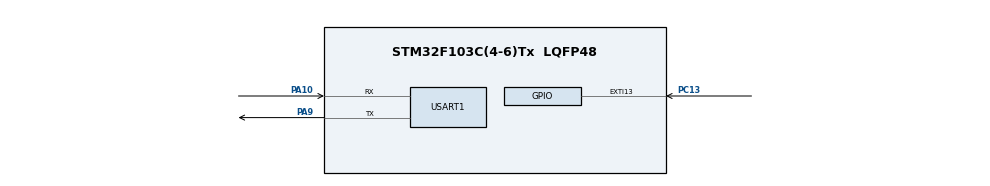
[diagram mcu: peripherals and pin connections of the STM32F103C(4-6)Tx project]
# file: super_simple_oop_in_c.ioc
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FREERTOS.Tasks01=mainTask,24,128,StartMainTask,Default,NULL,Dynamic,NULL,NULL
Mcu.Family=STM32F1
Mcu.Name=STM32F103C(4-6)Tx
Mcu.Package=LQFP48
NVIC.PriorityGroup=NVIC_PRIORITYGROUP_4
NVIC.TIM1_UP_IRQn=true\:15\:0\:false\:false\:true\:false\:false\:true\:true
NVIC.TimeBase=TIM1_UP_IRQn
NVIC.TimeBaseIP=TIM1
PA10.Mode=Asynchronous
PA10.Signal=USART1_RX
PA9.Mode=Asynchronous
PA9.Signal=USART1_TX
PC13-TAMPER-RTC.Signal=GPXTI13
ProjectManager.HeapSize=0x200
ProjectManager.StackSize=0x400
ProjectManager.TargetToolchain=Makefile
RCC.APB1Freq_Value=8000000
RCC.APB2Freq_Value=8000000
USART1.VirtualMode=VM_ASYNC
VP_FREERTOS_VS_CMSIS_V2.Mode=CMSIS_V2
VP_SYS_VS_ND.Mode=No_Debug
VP_SYS_VS_tim1.Mode=TIM1
board=custom

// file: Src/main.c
/* USER CODE BEGIN Header */
/**
 ******************************************************************************
 * @file           : main.c
 * @brief          : Main program body
 ******************************************************************************
 * @attention
 *
 * Copyright (c) 2023 STMicroelectronics.
 * All rights reserved.
 *
 * This software is licensed under terms that can be found in the LICENSE file
 * in the root directory of this software component.
 * If no LICENSE file comes with this software, it is provided AS-IS.
 *
 ******************************************************************************
 */
/* USER CODE END Header */
#include "main.h"
#include "cmsis_os.h"
#include "usart.h"
#include "gpio.h"

void SystemClock_Config(void);
void MX_FREERTOS_Init(void);

int main(void)
{

  /* MCU Configuration--------------------------------------------------------*/

  /* Reset of all peripherals, Initializes the Flash interface and the Systick. */
  HAL_Init();

  /* Configure the system clock */
  SystemClock_Config();

  /* Initialize all configured peripherals */
  MX_GPIO_Init();
  MX_USART1_UART_Init();

  /* Init scheduler */
  osKernelInitialize(); /* Call init function for freertos objects (in freertos.c) */
  MX_FREERTOS_Init();

  /* Start scheduler */
  osKernelStart();

  /* We should never get here as control is now taken by the scheduler */
  /* Infinite loop */
  while (1)
  {

  }
}

void SystemClock_Config(void)
{
  RCC_OscInitTypeDef RCC_OscInitStruct = {0};
  RCC_ClkInitTypeDef RCC_ClkInitStruct = {0};

  /** Initializes the RCC Oscillators according to the specified parameters
   * in the RCC_OscInitTypeDef structure.
   */
  RCC_OscInitStruct.OscillatorType = RCC_OSCILLATORTYPE_HSI;
  RCC_OscInitStruct.HSIState = RCC_HSI_ON;
  RCC_OscInitStruct.HSICalibrationValue = RCC_HSICALIBRATION_DEFAULT;
  RCC_OscInitStruct.PLL.PLLState = RCC_PLL_NONE;
  if (HAL_RCC_OscConfig(&RCC_OscInitStruct) != HAL_OK)
  {
    Error_Handler();
  }

  /** Initializes the CPU, AHB and APB buses clocks
   */
  RCC_ClkInitStruct.ClockType = RCC_CLOCKTYPE_HCLK | RCC_CLOCKTYPE_SYSCLK | RCC_CLOCKTYPE_PCLK1 | RCC_CLOCKTYPE_PCLK2;
  RCC_ClkInitStruct.SYSCLKSource = RCC_SYSCLKSOURCE_HSI;
  RCC_ClkInitStruct.AHBCLKDivider = RCC_SYSCLK_DIV1;
  RCC_ClkInitStruct.APB1CLKDivider = RCC_HCLK_DIV1;
  RCC_ClkInitStruct.APB2CLKDivider = RCC_HCLK_DIV1;

  if (HAL_RCC_ClockConfig(&RCC_ClkInitStruct, FLASH_LATENCY_0) != HAL_OK)
  {
    Error_Handler();
  }
}

void HAL_TIM_PeriodElapsedCallback(TIM_HandleTypeDef *htim)
{
  if (htim->Instance == TIM1)
  {
    HAL_IncTick();
  }
}

void Error_Handler(void)
{
  __disable_irq();
  while (1)
  {
  }
}

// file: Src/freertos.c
/* USER CODE BEGIN Header */
/**
 ******************************************************************************
 * File Name          : freertos.c
 * Description        : Code for freertos applications
 ******************************************************************************
 * @attention
 *
 * Copyright (c) 2023 STMicroelectronics.
 * All rights reserved.
 *
 * This software is licensed under terms that can be found in the LICENSE file
 * in the root directory of this software component.
 * If no LICENSE file comes with this software, it is provided AS-IS.
 *
 ******************************************************************************
 */
/* USER CODE END Header */

#include "FreeRTOS.h"
#include "task.h"
#include "main.h"
#include "cmsis_os.h"

/* USER CODE BEGIN Includes */
#include "point.h"
#include <string.h>
#include "math.h"
#include <stdio.h>
/* USER CODE END Includes */

/* USER CODE BEGIN Variables */
UART_HandleTypeDef huart1;
/* USER CODE END Variables */
/* Definitions for mainTask */
osThreadId_t mainTaskHandle;
const osThreadAttr_t mainTask_attributes = {
    .name = "mainTask",
    .stack_size = 128 * 4,
    .priority = (osPriority_t)osPriorityNormal,
};

void StartMainTask(void *argument);

void MX_FREERTOS_Init(void); /* (MISRA C 2004 rule 8.1) */

void MX_FREERTOS_Init(void)
{

  /* Create the thread(s) */
  /* creation of mainTask */
  mainTaskHandle = osThreadNew(StartMainTask, NULL, &mainTask_attributes);

}

void StartMainTask(void *argument)
{
  /* USER CODE BEGIN StartMainTask */
  /* Infinite loop */
  for (;;)
  {
    struct point *mypoint = point_create();
    mypoint->point_setCoordinates(mypoint, 10000.1, 20.2);
    int value = point_getXCoordinate(mypoint);
    int ndigit = 6;
    char buffer[ndigit];
    itoa(value, buffer, 10);
    char const *new_line = "\n";
    strcat(buffer, new_line);
    HAL_UART_Transmit(&huart1, (uint8_t *)buffer, strlen((const char *)buffer), 500);
    osDelay(1000);
  }
  /* USER CODE END StartMainTask */
}
